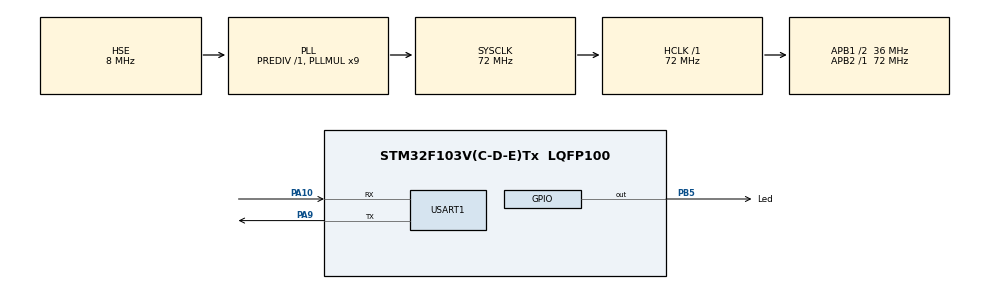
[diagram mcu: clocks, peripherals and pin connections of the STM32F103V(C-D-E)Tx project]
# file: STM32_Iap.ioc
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Dma.Request0=USART1_RX
Dma.Request1=USART1_TX
Dma.USART1_RX.0.Direction=DMA_PERIPH_TO_MEMORY
Dma.USART1_RX.0.Instance=DMA1_Channel5
Dma.USART1_RX.0.MemDataAlignment=DMA_MDATAALIGN_BYTE
Dma.USART1_RX.0.MemInc=DMA_MINC_ENABLE
Dma.USART1_RX.0.Mode=DMA_CIRCULAR
Dma.USART1_RX.0.PeriphDataAlignment=DMA_PDATAALIGN_BYTE
Dma.USART1_RX.0.PeriphInc=DMA_PINC_DISABLE
Dma.USART1_RX.0.Priority=DMA_PRIORITY_LOW
Dma.USART1_TX.1.Direction=DMA_MEMORY_TO_PERIPH
Dma.USART1_TX.1.Instance=DMA1_Channel4
Dma.USART1_TX.1.MemDataAlignment=DMA_MDATAALIGN_BYTE
Dma.USART1_TX.1.MemInc=DMA_MINC_ENABLE
Dma.USART1_TX.1.Mode=DMA_NORMAL
Dma.USART1_TX.1.PeriphDataAlignment=DMA_PDATAALIGN_BYTE
Dma.USART1_TX.1.PeriphInc=DMA_PINC_DISABLE
Dma.USART1_TX.1.Priority=DMA_PRIORITY_LOW
Mcu.Family=STM32F1
Mcu.Name=STM32F103V(C-D-E)Tx
Mcu.Package=LQFP100
NVIC.DMA1_Channel4_IRQn=true\:0\:0\:false\:false\:true\:false\:true
NVIC.DMA1_Channel5_IRQn=true\:0\:0\:false\:false\:true\:false\:true
NVIC.PriorityGroup=NVIC_PRIORITYGROUP_4
NVIC.USART1_IRQn=true\:0\:0\:false\:false\:true\:true\:true
OSC_IN.Mode=HSE-External-Oscillator
OSC_IN.Signal=RCC_OSC_IN
OSC_OUT.Mode=HSE-External-Oscillator
OSC_OUT.Signal=RCC_OSC_OUT
PA10.Mode=Asynchronous
PA10.Signal=USART1_RX
PA9.Mode=Asynchronous
PA9.Signal=USART1_TX
PB5.GPIO_Label=Led
PB5.Signal=GPIO_Output
PC14-OSC32_IN.Mode=LSE-External-Oscillator
PC14-OSC32_IN.Signal=RCC_OSC32_IN
PC15-OSC32_OUT.Mode=LSE-External-Oscillator
PC15-OSC32_OUT.Signal=RCC_OSC32_OUT
ProjectManager.HeapSize=0x200
ProjectManager.StackSize=0x400
ProjectManager.TargetToolchain=MDK-ARM V5
RCC.AHBFreq_Value=72000000
RCC.APB1CLKDivider=RCC_HCLK_DIV2
RCC.APB1Freq_Value=36000000
RCC.APB1TimFreq_Value=72000000
RCC.APB2Freq_Value=72000000
RCC.APB2TimFreq_Value=72000000
RCC.HCLKFreq_Value=72000000
RCC.PLLMUL=RCC_PLL_MUL9
RCC.PLLSourceVirtual=RCC_PLLSOURCE_HSE
RCC.SYSCLKFreq_VALUE=72000000
RCC.SYSCLKSource=RCC_SYSCLKSOURCE_PLLCLK
RCC.USBFreq_Value=48000000
RCC.USBPrescaler=RCC_USBCLKSOURCE_PLL_DIV1_5
USART1.VirtualMode=VM_ASYNC
VP_SYS_VS_ND.Mode=No_Debug
board=custom

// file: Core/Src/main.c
/* USER CODE BEGIN Header */
/**
  ******************************************************************************
  * @file           : main.c
  * @brief          : Main program body
  ******************************************************************************
  * @attention
  *
  * <h2><center>&copy; Copyright (c) 2019 STMicroelectronics.
  * All rights reserved.</center></h2>
  *
  * This software component is licensed by ST under BSD 3-Clause license,
  * the "License"; You may not use this file except in compliance with the
  * License. You may obtain a copy of the License at:
  *                        opensource.org/licenses/BSD-3-Clause
  *
  ******************************************************************************
  */
/* USER CODE END Header */

#include "main.h"
#include "dma.h"
#include "usart.h"
#include "gpio.h"

/* USER CODE BEGIN PV */
uint8_t GoToApp = 0;
/* USER CODE END PV */

void SystemClock_Config(void);

int main(void)
{
  /* USER CODE BEGIN 1 */
  pFunction JumpToApplication;
  uint32_t JumpAddress;
  /* USER CODE END 1 */

  /* MCU Configuration--------------------------------------------------------*/

  /* Reset of all peripherals, Initializes the Flash interface and the Systick. */
  HAL_Init();

  /* Configure the system clock */
  SystemClock_Config();

  /* Initialize all configured peripherals */
  MX_GPIO_Init();
  MX_DMA_Init();
  MX_USART1_UART_Init();

  /* Infinite loop */
  while (1)
  {

    /* USER CODE BEGIN 3 */
		if (GoToApp) {
			if (((*(__IO uint32_t *) APP_DEFAULT_ADD) & 0x2FFE0000) ==
					0x20000000)
			{
				/* Jump to user application */
				JumpAddress = *(__IO uint32_t *) (APP_DEFAULT_ADD + 4);
				JumpToApplication = (pFunction) JumpAddress;

				/* Initialize user application's Stack Pointer */
				__set_MSP(*(__IO uint32_t *) APP_DEFAULT_ADD);
				JumpToApplication();
			}
		}
  }
  /* USER CODE END 3 */
}

void SystemClock_Config(void)
{
  RCC_OscInitTypeDef RCC_OscInitStruct = {0};
  RCC_ClkInitTypeDef RCC_ClkInitStruct = {0};

  /** Initializes the CPU, AHB and APB busses clocks
  */
  RCC_OscInitStruct.OscillatorType = RCC_OSCILLATORTYPE_HSE;
  RCC_OscInitStruct.HSEState = RCC_HSE_ON;
  RCC_OscInitStruct.HSEPredivValue = RCC_HSE_PREDIV_DIV1;
  RCC_OscInitStruct.HSIState = RCC_HSI_ON;
  RCC_OscInitStruct.PLL.PLLState = RCC_PLL_ON;
  RCC_OscInitStruct.PLL.PLLSource = RCC_PLLSOURCE_HSE;
  RCC_OscInitStruct.PLL.PLLMUL = RCC_PLL_MUL9;
  if (HAL_RCC_OscConfig(&RCC_OscInitStruct) != HAL_OK)
  {
    Error_Handler();
  }
  /** Initializes the CPU, AHB and APB busses clocks
  */
  RCC_ClkInitStruct.ClockType = RCC_CLOCKTYPE_HCLK|RCC_CLOCKTYPE_SYSCLK
                              |RCC_CLOCKTYPE_PCLK1|RCC_CLOCKTYPE_PCLK2;
  RCC_ClkInitStruct.SYSCLKSource = RCC_SYSCLKSOURCE_PLLCLK;
  RCC_ClkInitStruct.AHBCLKDivider = RCC_SYSCLK_DIV1;
  RCC_ClkInitStruct.APB1CLKDivider = RCC_HCLK_DIV2;
  RCC_ClkInitStruct.APB2CLKDivider = RCC_HCLK_DIV1;

  if (HAL_RCC_ClockConfig(&RCC_ClkInitStruct, FLASH_LATENCY_2) != HAL_OK)
  {
    Error_Handler();
  }
}

/* USER CODE BEGIN 4 */
void HAL_UART_RxCpltCallback(UART_HandleTypeDef *huart)
{
  /* Prevent unused argument(s) compilation warning */
  if(huart == &huart1) {
    IAP_ProcessPack();
  }
  /* NOTE: This function Should not be modified, when the callback is needed,
           the HAL_UART_RxCpltCallback could be implemented in the user file
   */
}

void HAL_UART_TxCpltCallback(UART_HandleTypeDef *huart)
{
  /* Prevent unused argument(s) compilation warning */

  /* NOTE: This function Should not be modified, when the callback is needed,
           the HAL_UART_TxCpltCallback could be implemented in the user file
   */
}

void HAL_UART_ErrorCallback(UART_HandleTypeDef *huart)
{
  /* Prevent unused argument(s) compilation warning */

  /* NOTE: This function Should not be modified, when the callback is needed,
           the HAL_UART_ErrorCallback could be implemented in the user file
   */
}
/* USER CODE END 4 */

void Error_Handler(void)
{
}

/************************ (C) COPYRIGHT STMicroelectronics *****END OF FILE****/
